# SYSC register map
Vendor: Texas Instruments
Peripheral module from a debugger description file (folder omap5430_ES2_PUBLIC).
Registers are 32-bit, access per field, reset 0x0 unless marked. A register's access mark holds for its fields unless they carry their own. Offsets are as the file gives them; lines under a group give offsets from that group; [hi:lo] are bit positions; {n}, {i} and the like mark numbered series; 'fields as' and 'values as' point back to an identical list; <NAME> marks a mode.

## SYSC
0x00 SYSC_REVISION ro reset not defined — This register contains the IP revision code
  [31:0] REVISION — IP Revision
0x08 SYSC_SYSCONFIG rw reset 0x1 — This register allows controlling various parameters of the SYSC module
  [0] AUTOIDLE — Internal auto-clock gating strategy 0: Clock is free running 1: Automatic clock gating strategy is applied
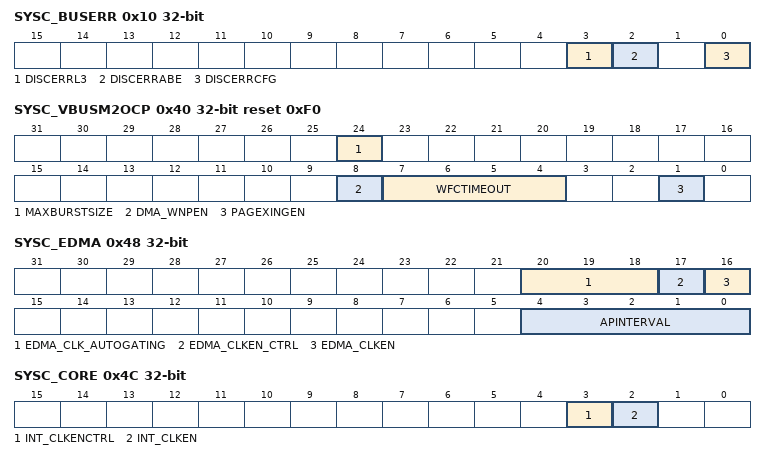
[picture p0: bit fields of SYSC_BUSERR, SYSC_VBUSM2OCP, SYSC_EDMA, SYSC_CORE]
0x10 SYSC_BUSERR access not given — store bus error information
  [3] DISCERRL3 — OCP Disconnect Bus Error status of L3 (access RW W1toClr)
  [2] DISCERRABE — OCP Disconnect Bus Error status of ABE (access RW W1toClr)
  [0] DISCERRCFG — OCP Disconnect Bus Error status of CFG (access RW W1toClr)
0x40 SYSC_VBUSM2OCP reset 0xF0 — This register controls the VBUSM2OCP bridge.
  [24] MAXBURSTSIZE rw — V2O burst maximum size 1: Burst maximum size is unknown. 0: Burst maximum size is 8.
  [8] DMA_WNPEN rw — DMA write nonposted enable 0: DMA write access is write posted only. 1: Enable convert write access to write nonposted.
  [7:4] WFCTIMEOUT rw — VBUSM2OCP burst closing timeout: The value drives the number of cycles the bridge waits without any new requests coming in before it automatically closes a burst.
  [1] PAGEXINGEN rw — MMU page crossing enable: 0: Bursts are not allowed to cross 4kB page boundaries 1: Bursts are allowed to cross 4kB page boundaries
0x48 SYSC_EDMA — This register allows controlling various parameters of the SCRM and SCRP local interconnects
  [20:18] EDMA_CLK_AUTOGATING rw — DMA_DSP clock autogating[18] is for TPCC (no actual clock gating, same as IVA2.2). . 19] is for TPTC0. . [20] is for TPTC1. .
    0=DMA_DSP_0 (DMA_DSP root clock is not autogated by hardware.); 1=DMA_DSP_1 (DMA_DSP root clock is autogated by hardware.)
  [17] EDMA_CLKEN_CTRL rw — DMA_DSP clock control enable
    0=DMA_DSP_0 (DMA_DSP clock is controlled by hardware.); 1=DMA_DSP_EDMA_CLKEN._1 (DMA_DSP clock is controlled by [16] EDMA_CLKEN.)
  [16] EDMA_CLKEN rw — DMA_DSP clock enableWhen SYSC_EDMA_CTRL[17] EDMA_CLKEN_CTRL = 1, then: . EDMA_CLKEN is for TPCC, TPTC0, and TPTC1. .
    0=DMA_DSP_clock_is_disabled; 1=DMA_DSP_clock_is_enabled
  [4:0] APINTERVAL rw — Control of the Aged Priority (priority inversion) for DMA accesses: When set to 0x0, the aged priority is disabled when set to another value. This controls how often the priority is adjusted: every APInterval cycle, the priority of the port is decreased until the associated request is accepted or the priority of the port equals 0. The priority of the port is reinitialized to the transaction priority each time a new VBUS command is generated, that is, the last one has been accepted.
    0=SCR._DMA_0 (Aged Priority Disabled: There is no aged priority in SCR. DMA transaction keeps the fixed priority defined internally, and has to wait for the bus to be freed by higher priority initiatorsAged Priority Disabled:)
0x4C SYSC_CORE
  [3] INT_CLKENCTRL rw — DSP core local clock-gating control
    0=DSP_0 (DSP core root clock is controlled by hardware.); 1=DSP_INT_CLKEN._1 (DSP core root clock is controlled by[2] INT_CLKEN.)
  [2] INT_CLKEN rw — DSP core local clock gate enabledWhen[3] INT_CLKENCTRL = 1, then: .
    0=DSP_core_clock_is_disabled; 1=DSP_core_clock_is_enabled
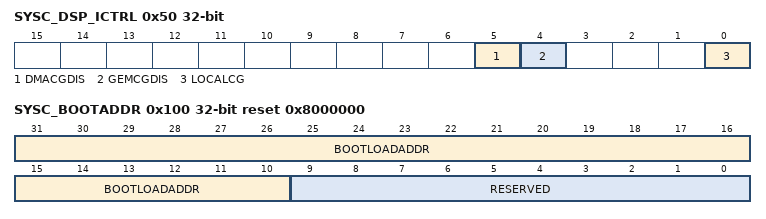
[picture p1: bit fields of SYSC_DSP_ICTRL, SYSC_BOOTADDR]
0x50 SYSC_DSP_ICTRL — This register allows controlling local to DSP subsystem clock gating
  [5] DMACGDIS rw — DMA local clock gating disable bit (only applicable when LOCALCG=1): 0: DMA clock can be stopped locally 1: DMA clock can not be stopped locally
  [4] GEMCGDIS rw — GEM local clock gating disable bit (only applicable when LOCALCG=1): 0: GEM clock can be stopped locally 1: GEM clock can not be stopped locally
  [0] LOCALCG rw — Internal auto-clock gating strategy 0: Global DSP power management (DMA and GEM clocks are not stopped independently but very low power state can be reached) 1: Local DSP power management (DMA and GEM clocks can be stopped independently but very low power state cannot be reached)
0x100 SYSC_BOOTADDR ro reset 0x8000000 — This register defines the physical address of the DSP boot loader. This is a copy of the CONTROL_DSP_BOOTADDR when the DSP is released from reset.
  [31:10] BOOTLOADADDR — Physical address of the DSP boot loader: This is the read-only copy of the CONTROL_DSP_BOOTADDR when the DSP is released from reset.
  [9:0] RESERVED — Reads return 0s.
0xF08 SYSC_IDLEDLY reset 0x20 — configurable idle delay counter
  [6:1] IDLEDELAYCNT rw — Idle Delay Counter
